# PIC32CZ2038CA70144 device description
Architecture: CORTEX-M7; Family: PIC32CZ; Series: CA70
Registers are 32-bit, read-write, no defined reset value unless marked. A register's access mark holds for its fields unless they carry their own. Offsets are from the block's base; [hi:lo] are bit positions; lines under a group give offsets from that group; {n}, {i} and the like mark numbered series; 'fields as' and 'values as' point back to an identical list.

## PWMC — Pulse Width Modulation Controller
Instances: PWMC0 0x40020000, PWMC1 0x4005C000
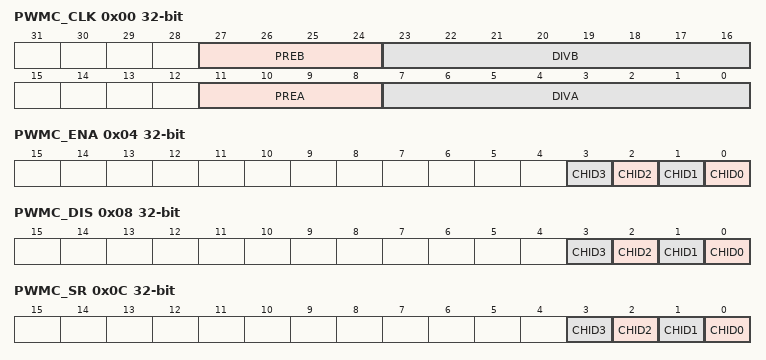
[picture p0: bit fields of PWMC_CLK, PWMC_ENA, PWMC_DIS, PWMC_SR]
0x00 PWMC_CLK — PWMC Clock Register
  [27:24] PREB — CLKB Source Clock Selection
    0=CLK (Peripheral clock); 1=CLK_DIV2 (Peripheral clock/2); 2=CLK_DIV4 (Peripheral clock/4); 3=CLK_DIV8 (Peripheral clock/8); 4=CLK_DIV16 (Peripheral clock/16); 5=CLK_DIV32 (Peripheral clock/32); 6=CLK_DIV64 (Peripheral clock/64); 7=CLK_DIV128 (Peripheral clock/128); 8=CLK_DIV256 (Peripheral clock/256); 9=CLK_DIV512 (Peripheral clock/512); 10=CLK_DIV1024 (Peripheral clock/1024)
  [23:16] DIVB — CLKB Divide Factor
    0=CLKB_POFF (CLKB clock is turned off); 1=PREB (CLKB clock is clock selected by PREB)
  [11:8] PREA — CLKA Source Clock Selection
    values as PREB
  [7:0] DIVA — CLKA Divide Factor
    0=CLKA_POFF (CLKA clock is turned off); 1=PREA (CLKA clock is clock selected by PREA)
0x04 PWMC_ENA wo — PWMC Enable Register
  [n] CHID{n} (n=0..3) — Channel ID
0x08 PWMC_DIS wo — PWMC Disable Register
  [n] CHID{n} (n=0..3) — Channel ID
0x0C PWMC_SR ro — PWMC Status Register
  [n] CHID{n} (n=0..3) — Channel ID
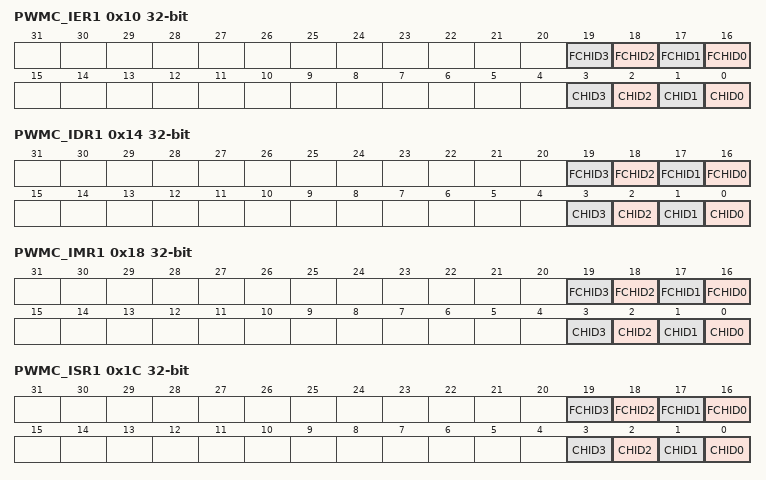
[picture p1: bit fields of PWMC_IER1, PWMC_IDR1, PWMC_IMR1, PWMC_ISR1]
0x10 PWMC_IER1 wo (atomic set of PWMC_IMR1) — PWMC Interrupt Enable Register 1
  [n+16] FCHID{n} (n=0..3) — Fault Protection Trigger on Channel {n} Interrupt Enable
  [n] CHID{n} (n=0..3) — Counter Event on Channel {n} Interrupt Enable
0x14 PWMC_IDR1 wo (atomic clear of PWMC_IMR1) — PWMC Interrupt Disable Register 1
  [n+16] FCHID{n} (n=0..3) — Fault Protection Trigger on Channel {n} Interrupt Disable
  [n] CHID{n} (n=0..3) — Counter Event on Channel {n} Interrupt Disable
0x18 PWMC_IMR1 ro (atomic read) — PWMC Interrupt Mask Register 1
  [n+16] FCHID{n} (n=0..3) — Fault Protection Trigger on Channel {n} Interrupt Mask
  [n] CHID{n} (n=0..3) — Counter Event on Channel {n} Interrupt Mask
0x1C PWMC_ISR1 ro (atomic clear) — PWMC Interrupt Status Register 1
  [n+16] FCHID{n} (n=0..3) — Fault Protection Trigger on Channel {n}
  [n] CHID{n} (n=0..3) — Counter Event on Channel {n}
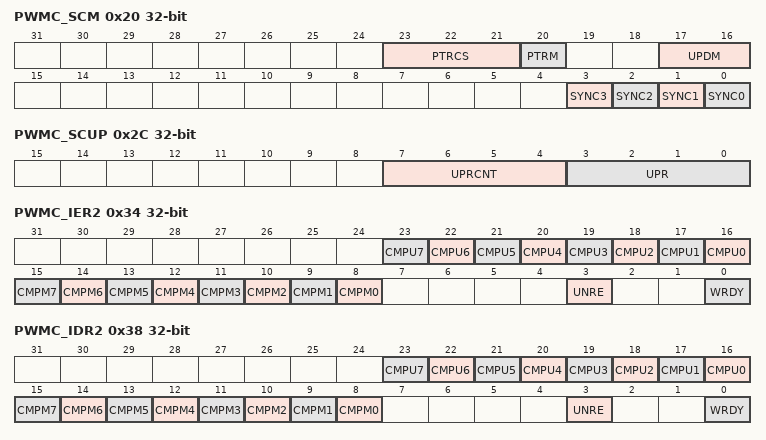
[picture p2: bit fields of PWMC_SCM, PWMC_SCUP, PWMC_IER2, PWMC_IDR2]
0x20 PWMC_SCM — PWMC Sync Channels Mode Register
  [23:21] PTRCS — DMA Controller Transfer Request Comparison Selection
  [20] PTRM — DMA Controller Transfer Request Mode
  [17:16] UPDM — Synchronous Channels Update Mode
  [n] SYNC{n} (n=0..3) — Synchronous Channel {n}
0x24 PWMC_DMAR wo — PWMC DMA Register
  [23:0] DMADUTY — Duty-Cycle Holding Register for DMA Access
0x28 PWMC_SCUC — PWMC Sync Channels Update Control Register
  [0] UPDULOCK — Synchronous Channels Update Unlock
0x2C PWMC_SCUP — PWMC Sync Channels Update Period Register
  [7:4] UPRCNT — Update Period Counter
  [3:0] UPR — Update Period
0x30 PWMC_SCUPUPD wo — PWMC Sync Channels Update Period Update Register
  [3:0] UPRUPD — Update Period Update
0x34 PWMC_IER2 wo (atomic set of PWMC_IMR2) — PWMC Interrupt Enable Register 2
  [n+16] CMPU{n} (n=0..7) — Comparison {n} Update Interrupt Enable
  [n+8] CMPM{n} (n=0..7) — Comparison {n} Match Interrupt Enable
  [3] UNRE — Synchronous Channels Update Underrun Error Interrupt Enable
  [0] WRDY — Write Ready for Synchronous Channels Update Interrupt Enable
0x38 PWMC_IDR2 wo (atomic clear of PWMC_IMR2) — PWMC Interrupt Disable Register 2
  [n+16] CMPU{n} (n=0..7) — Comparison {n} Update Interrupt Disable
  [n+8] CMPM{n} (n=0..7) — Comparison {n} Match Interrupt Disable
  [3] UNRE — Synchronous Channels Update Underrun Error Interrupt Disable
  [0] WRDY — Write Ready for Synchronous Channels Update Interrupt Disable
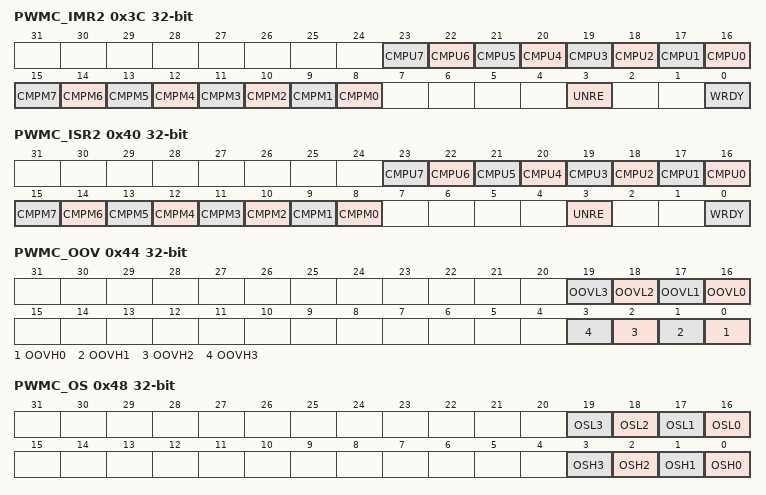
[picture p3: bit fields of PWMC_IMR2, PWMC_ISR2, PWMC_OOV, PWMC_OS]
0x3C PWMC_IMR2 ro (atomic read) — PWMC Interrupt Mask Register 2
  [n+16] CMPU{n} (n=0..7) — Comparison {n} Update Interrupt Mask
  [n+8] CMPM{n} (n=0..7) — Comparison {n} Match Interrupt Mask
  [3] UNRE — Synchronous Channels Update Underrun Error Interrupt Mask
  [0] WRDY — Write Ready for Synchronous Channels Update Interrupt Mask
0x40 PWMC_ISR2 ro (atomic clear) — PWMC Interrupt Status Register 2
  [n+16] CMPU{n} (n=0..7) — Comparison {n} Update
  [n+8] CMPM{n} (n=0..7) — Comparison {n} Match
  [3] UNRE — Synchronous Channels Update Underrun Error
  [0] WRDY — Write Ready for Synchronous Channels Update
0x44 PWMC_OOV — PWMC Output Override Value Register
  [n+16] OOVL{n} (n=0..3) — Output Override Value for PWML output of the channel {n}
  [n] OOVH{n} (n=0..3) — Output Override Value for PWMH output of the channel {n}
0x48 PWMC_OS — PWMC Output Selection Register
  [n+16] OSL{n} (n=0..3) — Output Selection for PWML output of the channel {n}
  [n] OSH{n} (n=0..3) — Output Selection for PWMH output of the channel {n}
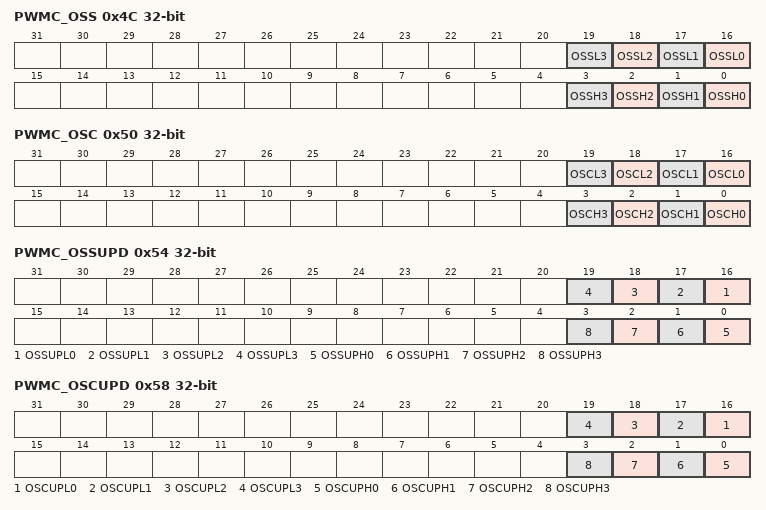
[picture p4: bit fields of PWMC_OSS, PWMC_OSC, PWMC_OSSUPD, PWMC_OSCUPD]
0x4C PWMC_OSS wo — PWMC Output Selection Set Register
  [n+16] OSSL{n} (n=0..3) — Output Selection Set for PWML output of the channel {n}
  [n] OSSH{n} (n=0..3) — Output Selection Set for PWMH output of the channel {n}
0x50 PWMC_OSC wo — PWMC Output Selection Clear Register
  [n+16] OSCL{n} (n=0..3) — Output Selection Clear for PWML output of the channel {n}
  [n] OSCH{n} (n=0..3) — Output Selection Clear for PWMH output of the channel {n}
0x54 PWMC_OSSUPD wo — PWMC Output Selection Set Update Register
  [n+16] OSSUPL{n} (n=0..3) — Output Selection Set for PWML output of the channel {n}
  [n] OSSUPH{n} (n=0..3) — Output Selection Set for PWMH output of the channel {n}
0x58 PWMC_OSCUPD wo — PWMC Output Selection Clear Update Register
  [n+16] OSCUPL{n} (n=0..3) — Output Selection Clear for PWML output of the channel {n}
  [n] OSCUPH{n} (n=0..3) — Output Selection Clear for PWMH output of the channel {n}
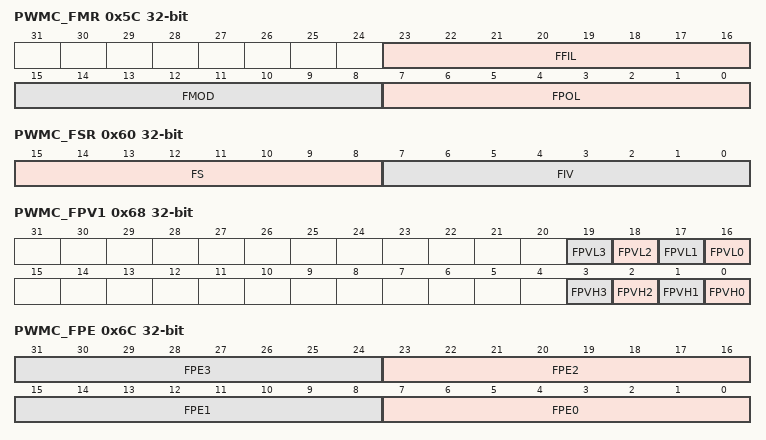
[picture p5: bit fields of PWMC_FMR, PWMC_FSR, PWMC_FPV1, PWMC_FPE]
0x5C PWMC_FMR — PWMC Fault Mode Register
  [23:16] FFIL — Fault Filtering
  [15:8] FMOD — Fault Activation Mode
  [7:0] FPOL — Fault Polarity
0x60 PWMC_FSR ro — PWMC Fault Status Register
  [15:8] FS — Fault Status
  [7:0] FIV — Fault Input Value
0x64 PWMC_FCR wo — PWMC Fault Clear Register
  [7:0] FCLR — Fault Clear
0x68 PWMC_FPV1 — PWMC Fault Protection Value Register 1
  [n+16] FPVL{n} (n=0..3) — Fault Protection Value for PWML output on channel {n}
  [n] FPVH{n} (n=0..3) — Fault Protection Value for PWMH output on channel {n}
0x6C PWMC_FPE — PWMC Fault Protection Enable Register
  [8n+7:8n] FPE{n} (n=0..3) — Fault Protection Enable for channel {n}
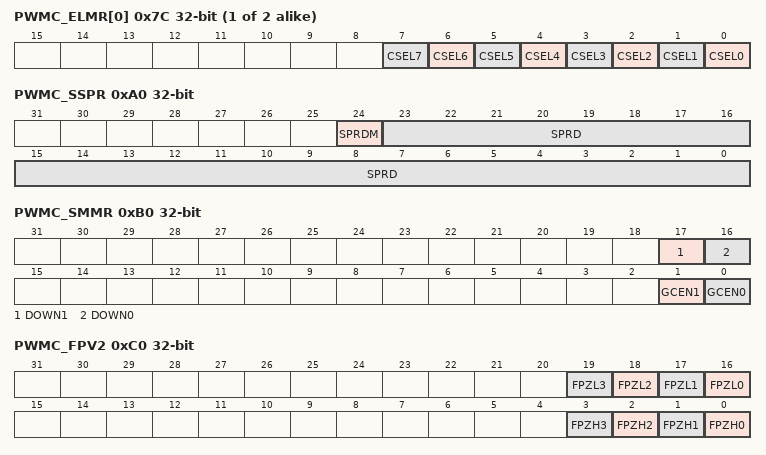
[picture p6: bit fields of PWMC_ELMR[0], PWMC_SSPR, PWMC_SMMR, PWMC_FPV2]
{0x7C+4i} PWMC_ELMR[{i}] (i=0..1) — PWMC Event Line 0 Mode Register 0
  [n] CSEL{n} (n=0..7) — Comparison {n} Selection
0xA0 PWMC_SSPR — PWMC Spread Spectrum Register
  [24] SPRDM — Spread Spectrum Counter Mode
  [23:0] SPRD — Spread Spectrum Limit Value
0xA4 PWMC_SSPUP wo — PWMC Spread Spectrum Update Register
  [23:0] SPRDUP — Spread Spectrum Limit Value Update
0xB0 PWMC_SMMR — PWMC Stepper Motor Mode Register
  [17] DOWN1 — DOWN Count
  [16] DOWN0 — DOWN Count
  [1] GCEN1 — Gray Count ENable
  [0] GCEN0 — Gray Count ENable
0xC0 PWMC_FPV2 — PWMC Fault Protection Value 2 Register
  [n+16] FPZL{n} (n=0..3) — Fault Protection to Hi-Z for PWML output on channel {n}
  [n] FPZH{n} (n=0..3) — Fault Protection to Hi-Z for PWMH output on channel {n}
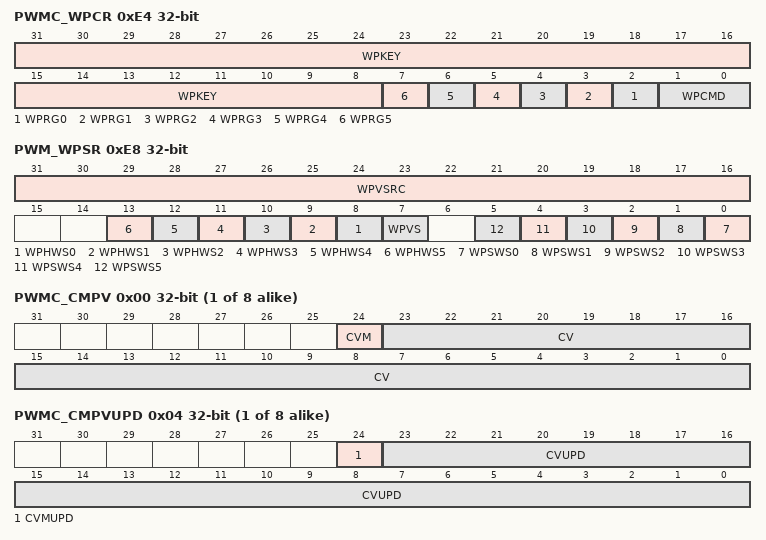
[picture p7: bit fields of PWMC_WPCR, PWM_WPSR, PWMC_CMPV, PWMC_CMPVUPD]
0xE4 PWMC_WPCR wo — PWMC Write Protection Control Register
  [31:8] WPKEY — Write Protection Key
    0x50574D=PASSWD (Writing any other value in this field aborts the write operation of the WPCMD field.Always reads as 0)
  [n+2] WPRG{n} (n=0..5) — Write Protection Register Group {n}
  [1:0] WPCMD — Write Protection Command
    0=DISABLE_SW_PROT (Disables the software write protection of the register groups of which the bit WPRGx is at '1'.); 1=ENABLE_SW_PROT (Enables the software write protection of the register groups of which the bit WPRGx is at '1'.); 2=ENABLE_HW_PROT (Enables the hardware write protection of the register groups of which the bit WPRGx is at '1'. Only a hardware reset of the PWM controller can disable the hardware write protection. Moreover, to meet security requirements, the PORT lines associated with the PWM can not be configured through the PORT interface.)
0xE8 PWM_WPSR ro — PWMC Write Protection Status Register
  [31:16] WPVSRC — Write Protect Violation Source
  [n+8] WPHWS{n} (n=0..5) — Write Protect HW Status
  [7] WPVS — Write Protect Violation Status
  [n] WPSWS{n} (n=0..5) — Write Protect SW Status
{0x130+0x10*i} PWMC_CMP[{i}] (i=0..7) group — PWMC Comparison 0 Value Register
  0x00 PWMC_CMPV — PWMC Comparison 0 Value Register
    [24] CVM — Comparison x Value Mode
    [23:0] CV — Comparison x Value
  0x04 PWMC_CMPVUPD wo — PWMC Comparison 0 Value Update Register
    [24] CVMUPD — Comparison x Value Mode Update
    [23:0] CVUPD — Comparison x Value Update
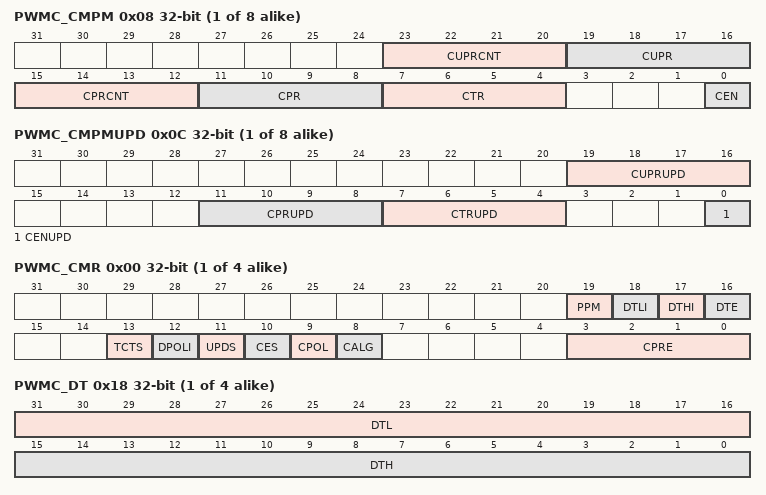
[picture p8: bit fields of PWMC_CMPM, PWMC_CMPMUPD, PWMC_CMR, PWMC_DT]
  0x08 PWMC_CMPM — PWMC Comparison 0 Mode Register
    [23:20] CUPRCNT — Comparison x Update Period Counter
    [19:16] CUPR — Comparison x Update Period
    [15:12] CPRCNT — Comparison x Period Counter
    [11:8] CPR — Comparison x Period
    [7:4] CTR — Comparison x Trigger
    [0] CEN — Comparison x Enable
  0x0C PWMC_CMPMUPD wo — PWMC Comparison 0 Mode Update Register
    [19:16] CUPRUPD — Comparison x Update Period Update
    [11:8] CPRUPD — Comparison x Period Update
    [7:4] CTRUPD — Comparison x Trigger Update
    [0] CENUPD — Comparison x Enable Update
{0x200+0x20*i} PWMC_CH_NUM[{i}] (i=0..3) group — PWMC Channel Mode Register (ch_num = 0)
  0x00 PWMC_CMR — PWMC Channel Mode Register (ch_num = 0)
    [19] PPM — Push-Pull Mode
    [18] DTLI — Dead-Time PWMLx Output Inverted
    [17] DTHI — Dead-Time PWMHx Output Inverted
    [16] DTE — Dead-Time Generator Enable
    [13] TCTS — Timer Counter Trigger Selection
    [12] DPOLI — Disabled Polarity Inverted
    [11] UPDS — Update Selection
    [10] CES — Counter Event Selection
    [9] CPOL — Channel Polarity
    [8] CALG — Channel Alignment
    [3:0] CPRE — Channel Pre-scaler
      0=MCK (Peripheral clock); 1=MCK_DIV_2 (Peripheral clock/2); 2=MCK_DIV_4 (Peripheral clock/4); 3=MCK_DIV_8 (Peripheral clock/8); 4=MCK_DIV_16 (Peripheral clock/16); 5=MCK_DIV_32 (Peripheral clock/32); 6=MCK_DIV_64 (Peripheral clock/64); 7=MCK_DIV_128 (Peripheral clock/128); 8=MCK_DIV_256 (Peripheral clock/256); 9=MCK_DIV_512 (Peripheral clock/512); 10=MCK_DIV_1024 (Peripheral clock/1024); 11=CLKA (Clock A); 12=CLKB (Clock B)
  0x04 PWMC_CDTY — PWMC Channel Duty Cycle Register (ch_num = 0)
    [23:0] CDTY — Channel Duty-Cycle
  0x08 PWMC_CDTYUPD wo — PWMC Channel Duty Cycle Update Register (ch_num = 0)
    [23:0] CDTYUPD — Channel Duty-Cycle Update
  0x0C PWMC_CPRD — PWMC Channel Period Register (ch_num = 0)
    [23:0] CPRD — Channel Period
  0x10 PWMC_CPRDUPD wo — PWMC Channel Period Update Register (ch_num = 0)
    [23:0] CPRDUPD — Channel Period Update
  0x14 PWMC_CCNT ro — PWMC Channel Counter Register (ch_num = 0)
    [23:0] CNT — Channel Counter Register
  0x18 PWMC_DT — PWMC Channel Dead Time Register (ch_num = 0)
    [31:16] DTL — Dead-Time Value for PWMLx Output
    [15:0] DTH — Dead-Time Value for PWMHx Output
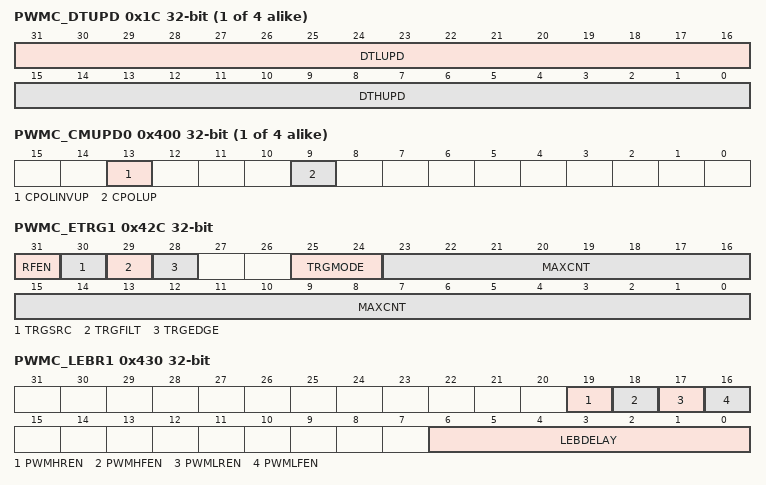
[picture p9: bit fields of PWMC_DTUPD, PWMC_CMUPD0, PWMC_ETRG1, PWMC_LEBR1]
  0x1C PWMC_DTUPD wo — PWMC Channel Dead Time Update Register (ch_num = 0)
    [31:16] DTLUPD — Dead-Time Value Update for PWMLx Output
    [15:0] DTHUPD — Dead-Time Value Update for PWMHx Output
{0x400+0x20*i} PWMC_CMUPD{i} wo (i=0..3) — PWMC Channel Mode Update Register (ch_num = {i})
  [13] CPOLINVUP — Channel Polarity Inversion Update
  [9] CPOLUP — Channel Polarity Update
0x42C PWMC_ETRG1 — PWMC External Trigger Register (trg_num = 1)
  [31] RFEN — Recoverable Fault Enable
  [30] TRGSRC — Trigger Source
  [29] TRGFILT — Filtered input
  [28] TRGEDGE — Edge Selection
    0=FALLING_ZERO (TRGMODE = 1: TRGINx event detection on falling edge.TRGMODE = 2, 3: TRGINx active level is 0); 1=RISING_ONE (TRGMODE = 1: TRGINx event detection on rising edge.TRGMODE = 2, 3: TRGINx active level is 1)
  [25:24] TRGMODE — External Trigger Mode
    0=OFF (External trigger is not enabled.); 1=MODE1 (External PWM Reset Mode); 2=MODE2 (External PWM Start Mode); 3=MODE3 (Cycle-by-cycle Duty Mode)
  [23:0] MAXCNT — Maximum Counter value
0x430 PWMC_LEBR1 — PWMC Leading-Edge Blanking Register (trg_num = 1)
  [19] PWMHREN — PWMH Rising Edge Enable
  [18] PWMHFEN — PWMH Falling Edge Enable
  [17] PWMLREN — PWML Rising Edge Enable
  [16] PWMLFEN — PWML Falling Edge Enable
  [6:0] LEBDELAY — Leading-Edge Blanking Delay for TRGINx
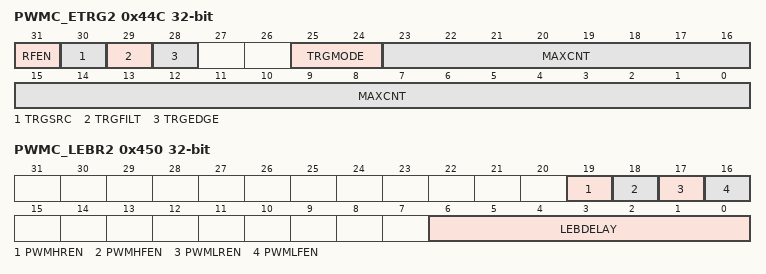
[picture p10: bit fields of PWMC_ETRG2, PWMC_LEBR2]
0x44C PWMC_ETRG2 — PWMC External Trigger Register (trg_num = 2)
  fields as PWMC_ETRG1
0x450 PWMC_LEBR2 — PWMC Leading-Edge Blanking Register (trg_num = 2)
  fields as PWMC_LEBR1
Value list PWMC_SCM__UPDM: 0=MODE0 (Manual write of double buffer registers and manual update of synchronous channels); 1=MODE1 (Manual write of double buffer registers and automatic update of synchronous channels); 2=MODE2 (Automatic write of duty-cycle update registers by the DMA Controller and automatic update of synchronous channels)
